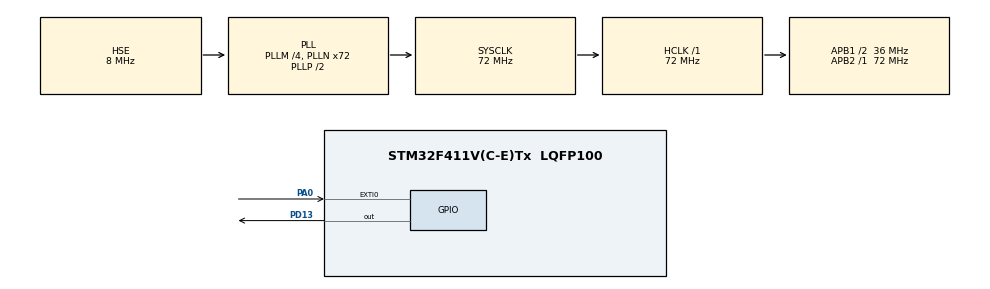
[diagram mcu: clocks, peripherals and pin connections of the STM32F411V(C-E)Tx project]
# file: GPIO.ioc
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Mcu.Family=STM32F4
Mcu.Name=STM32F411V(C-E)Tx
Mcu.Package=LQFP100
NVIC.EXTI0_IRQn=true\:0\:0\:false\:false\:true\:true\:true\:true
NVIC.PriorityGroup=NVIC_PRIORITYGROUP_0
PA0-WKUP.Signal=GPXTI0
PD13.Signal=GPIO_Output
PH0\ -\ OSC_IN.Mode=HSE-External-Oscillator
PH0\ -\ OSC_IN.Signal=RCC_OSC_IN
PH1\ -\ OSC_OUT.Mode=HSE-External-Oscillator
PH1\ -\ OSC_OUT.Signal=RCC_OSC_OUT
ProjectManager.HeapSize=0x200
ProjectManager.StackSize=0x400
ProjectManager.TargetToolchain=STM32CubeIDE
RCC.48MHZClocksFreq_Value=18000000
RCC.AHBFreq_Value=72000000
RCC.APB1CLKDivider=RCC_HCLK_DIV2
RCC.APB1Freq_Value=36000000
RCC.APB1TimFreq_Value=72000000
RCC.APB2Freq_Value=72000000
RCC.APB2TimFreq_Value=72000000
RCC.CortexFreq_Value=72000000
RCC.HCLKFreq_Value=72000000
RCC.HSE_VALUE=8000000
RCC.HSI_VALUE=16000000
RCC.LSE_VALUE=32768
RCC.PLLI2SM=5
RCC.PLLI2SN=200
RCC.PLLM=4
RCC.PLLN=72
RCC.PLLQ=8
RCC.PLLSourceVirtual=RCC_PLLSOURCE_HSE
RCC.SYSCLKFreq_VALUE=72000000
RCC.SYSCLKSource=RCC_SYSCLKSOURCE_PLLCLK
RCC.VCOOutputFreq_Value=144000000
board=STM32F411E-DISCO

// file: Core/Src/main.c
/* USER CODE BEGIN Header */
/**
  ******************************************************************************
  * @file           : main.c
  * @brief          : Main program body
  ******************************************************************************
  * @attention
  *
  * Copyright (c) 2024 STMicroelectronics.
  * All rights reserved.
  *
  * This software is licensed under terms that can be found in the LICENSE file
  * in the root directory of this software component.
  * If no LICENSE file comes with this software, it is provided AS-IS.
  *
  ******************************************************************************
  */
/* USER CODE END Header */
#include "main.h"

void SystemClock_Config(void);
static void MX_GPIO_Init(void);

/* USER CODE BEGIN 0 */
void HAL_GPIO_EXTI_Callback(uint16_t GPIO_Pin)
{
    if(GPIO_Pin == GPIO_PIN_0)
    {
    HAL_GPIO_TogglePin(GPIOD, GPIO_PIN_13); // Toggle The Output (LED) Pin
    }
}
void HAL_GPIO_EXTI0_IRQHandler(uint16_t GPIO_Pin)
{

  if (__HAL_GPIO_EXTI_GET_IT(GPIO_Pin) != 0x00u)
  {
    __HAL_GPIO_EXTI_CLEAR_IT(GPIO_Pin);
     HAL_GPIO_EXTI_Callback(GPIO_Pin);
  }
}
/* USER CODE END 0 */

int main(void)
{

  /* MCU Configuration--------------------------------------------------------*/

  /* Reset of all peripherals, Initializes the Flash interface and the Systick. */
  HAL_Init();

  /* Configure the system clock */
  SystemClock_Config();

  /* Initialize all configured peripherals */
  MX_GPIO_Init();

  /* Infinite loop */
  while (1)
  {

  }
}

void SystemClock_Config(void)
{
  RCC_OscInitTypeDef RCC_OscInitStruct = {0};
  RCC_ClkInitTypeDef RCC_ClkInitStruct = {0};

  /** Configure the main internal regulator output voltage
  */
  __HAL_RCC_PWR_CLK_ENABLE();
  __HAL_PWR_VOLTAGESCALING_CONFIG(PWR_REGULATOR_VOLTAGE_SCALE1);

  /** Initializes the RCC Oscillators according to the specified parameters
  * in the RCC_OscInitTypeDef structure.
  */
  RCC_OscInitStruct.OscillatorType = RCC_OSCILLATORTYPE_HSE;
  RCC_OscInitStruct.HSEState = RCC_HSE_ON;
  RCC_OscInitStruct.PLL.PLLState = RCC_PLL_ON;
  RCC_OscInitStruct.PLL.PLLSource = RCC_PLLSOURCE_HSE;
  RCC_OscInitStruct.PLL.PLLM = 4;
  RCC_OscInitStruct.PLL.PLLN = 72;
  RCC_OscInitStruct.PLL.PLLP = RCC_PLLP_DIV2;
  RCC_OscInitStruct.PLL.PLLQ = 8;
  if (HAL_RCC_OscConfig(&RCC_OscInitStruct) != HAL_OK)
  {
    Error_Handler();
  }

  /** Initializes the CPU, AHB and APB buses clocks
  */
  RCC_ClkInitStruct.ClockType = RCC_CLOCKTYPE_HCLK|RCC_CLOCKTYPE_SYSCLK
                              |RCC_CLOCKTYPE_PCLK1|RCC_CLOCKTYPE_PCLK2;
  RCC_ClkInitStruct.SYSCLKSource = RCC_SYSCLKSOURCE_PLLCLK;
  RCC_ClkInitStruct.AHBCLKDivider = RCC_SYSCLK_DIV1;
  RCC_ClkInitStruct.APB1CLKDivider = RCC_HCLK_DIV2;
  RCC_ClkInitStruct.APB2CLKDivider = RCC_HCLK_DIV1;

  if (HAL_RCC_ClockConfig(&RCC_ClkInitStruct, FLASH_LATENCY_2) != HAL_OK)
  {
    Error_Handler();
  }
}

static void MX_GPIO_Init(void)
{
  GPIO_InitTypeDef GPIO_InitStruct = {0};

  /* GPIO Ports Clock Enable */
  __HAL_RCC_GPIOH_CLK_ENABLE();
  __HAL_RCC_GPIOA_CLK_ENABLE();
  __HAL_RCC_GPIOD_CLK_ENABLE();

  /*Configure GPIO pin Output Level */
  HAL_GPIO_WritePin(GPIOD, GPIO_PIN_13, GPIO_PIN_RESET);

  /*Configure GPIO pin : PA0 */
  GPIO_InitStruct.Pin = GPIO_PIN_0;
  GPIO_InitStruct.Mode = GPIO_MODE_IT_RISING;
  GPIO_InitStruct.Pull = GPIO_NOPULL;
  HAL_GPIO_Init(GPIOA, &GPIO_InitStruct);

  /*Configure GPIO pin : PD13 */
  GPIO_InitStruct.Pin = GPIO_PIN_13;
  GPIO_InitStruct.Mode = GPIO_MODE_OUTPUT_PP;
  GPIO_InitStruct.Pull = GPIO_NOPULL;
  GPIO_InitStruct.Speed = GPIO_SPEED_FREQ_LOW;
  HAL_GPIO_Init(GPIOD, &GPIO_InitStruct);

  /* EXTI interrupt init*/
  HAL_NVIC_SetPriority(EXTI0_IRQn, 0, 0);
  HAL_NVIC_EnableIRQ(EXTI0_IRQn);

}

void Error_Handler(void)
{
  __disable_irq();
  while (1)
  {
  }
}
